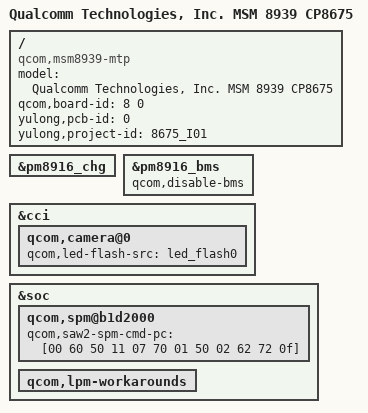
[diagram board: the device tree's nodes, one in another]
/* Copyright (c) 2014, The Linux Foundation. All rights reserved.
*
* This program is free software; you can redistribute it and/or modify
* it under the terms of the GNU General Public License version 2 and
* only version 2 as published by the Free Software Foundation.
*
* This program is distributed in the hope that it will be useful,
* but WITHOUT ANY WARRANTY; without even the implied warranty of
* MERCHANTABILITY or FITNESS FOR A PARTICULAR PURPOSE.  See the
* GNU General Public License for more details.
*/

/dts-v1/;

#include "msm8939.dtsi"
#include "msm8939-audio-internal_codec.dtsi"
#include "cp8675/msm8939-cp8675.dtsi"

/ {
	model = "Qualcomm Technologies, Inc. MSM 8939 CP8675";
	compatible = "qcom,msm8939-mtp", "qcom,msm8939", "qcom,mtp";
	qcom,board-id = <8 0>;
	yulong,pcb-id = <0>;
	yulong,project-id = "8675_I01";
};

&pm8916_chg {
	status = "ok";
};

&pm8916_bms {
	status = "ok";
	qcom,disable-bms;
};

&cci {
	qcom,camera@0 {
		qcom,led-flash-src = <&led_flash0>;
	};
};

&soc {
	qcom,spm@b1d2000 {
		qcom,saw2-spm-cmd-pc = [00 60 50 11 07 70 01 50 02 62 72 0f];
	};

	qcom,lpm-workarounds {
		/delete-property/ qcom,lpm-wa-skip-l2-spm;
	};
};
